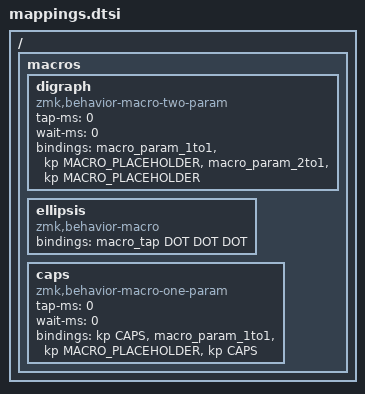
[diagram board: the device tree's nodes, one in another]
// from https://github.com/OneDeadKey/zmk-config-aekeynox/blob/pinky_mod_hold/include/aekeynox/mappings.dtsi

#include <behaviors.dtsi>
#include <dt-bindings/zmk/keys.h>

// Define a dead layer key
#define DEAD_KEY(name, key) OMIT_IF_NO_REF name: name { \
  compatible = "zmk,behavior-macro-one-param";          \
  #binding-cells = <1>;                                 \
  tap-ms = <0>;                                         \
  wait-ms = <0>;                                        \
  bindings                                              \
    = <&macro_tap key>                                  \
    , <&macro_param_1to1 &kp MACRO_PLACEHOLDER>         \
    ;                                                   \
};

// Define a shifted dead layer key
#define DEAD_KEY_SHIFT(name, key) OMIT_IF_NO_REF name: name { \
  compatible = "zmk,behavior-macro-one-param";                \
  #binding-cells = <1>;                                       \
  tap-ms = <0>;                                               \
  wait-ms = <0>;                                              \
  bindings                                                    \
    = <&macro_tap key>                                        \
    , <&macro_press &kp LSHIFT>                               \
    , <&macro_tap &macro_param_1to1 &kp MACRO_PLACEHOLDER>    \
    , <&macro_release &kp LSHIFT>                             \
    ;                                                         \
};

// Define a two-level key (e.g. punctuation key)
#define TWO_LEVEL_KEY(name, base, shift) OMIT_IF_NO_REF name: name { \
  compatible = "zmk,behavior-mod-morph";                             \
  #binding-cells = <0>;                                              \
  bindings = <base>, <shift>;                                        \
  mods = <(MOD_LSFT|MOD_RSFT)>;                                      \
};

/ {
  // behaviors {
  //   TWO_LEVEL_KEY(bt_sel1_clr, &bt BT_SEL 1, &bt BT_CLR)
  // };

  macros {

    OMIT_IF_NO_REF digraph: digraph {
      compatible = "zmk,behavior-macro-two-param";
      #binding-cells = <2>;
      tap-ms = <0>;
      wait-ms = <0>;
      bindings
        = <&macro_param_1to1 &kp MACRO_PLACEHOLDER>
        , <&macro_param_2to1 &kp MACRO_PLACEHOLDER>
        ;
    };

    OMIT_IF_NO_REF ellipsis: ellipsis {
      compatible = "zmk,behavior-macro";
      #binding-cells = <0>;
      bindings = <&macro_tap DOT DOT DOT>;
    };

    OMIT_IF_NO_REF caps: caps {
      compatible = "zmk,behavior-macro-one-param";
      #binding-cells = <1>;
      tap-ms = <0>;
      wait-ms = <0>;
      bindings
        = <&kp CAPS>
        , <&macro_param_1to1 &kp MACRO_PLACEHOLDER>
        , <&kp CAPS>
        ;
    };

  };
};
